# MCU_NAVSS0_RINGACC0_UDMASS_RINGACC0_CFG_MON register map
Vendor: Texas Instruments
Peripheral module from a debugger description file (folder J721S2).
Registers are 32-bit, read-write, reset 0x0 unless marked. A register's access mark holds for its fields unless they carry their own. Offsets are as the file gives them; lines under a group give offsets from that group; [hi:lo] are bit positions; {n}, {i} and the like mark numbered series; 'fields as' and 'values as' point back to an identical list; <NAME> marks a mode.

## MCU_NAVSS0_RINGACC0_UDMASS_RINGACC0_CFG_MON
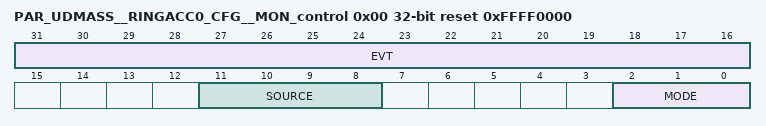
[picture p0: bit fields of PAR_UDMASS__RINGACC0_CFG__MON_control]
0x00 PAR_UDMASS__RINGACC0_CFG__MON_control reset 0xFFFF0000 — Monitor Control Register
  [31:16] EVT — Event to produce.
  [11:8] SOURCE — Monitor source selection. 0 = element count. 1 = reserved. 2 = reserved.
  [2:0] MODE — Monitor Mode. 0 = disabled. 1 = push/pop statistics capture. 2 = low/high threshold checks. 3 = low/high watermarking. 4 = starvation counting.
0x04 PAR_UDMASS__RINGACC0_CFG__MON_queue — Monitor Queue Register
  [15:0] QUEUE — Queue to monitor.
0x08 PAR_UDMASS__RINGACC0_CFG__MON_data0 — Monitor Data Register
  [31:0] DATA — Monitor Data. For mode 1 this is read-only and number of pushes. For mode 2 this is read-write and the low threshold value. For mode 3 this is read only and the low watermark. For mode 4 this is read only and the starvation count.
0x0C PAR_UDMASS__RINGACC0_CFG__MON_data1 — Monitor Data Register
  [31:0] DATA — Monitor Data. For mode 1 this is read-only and number of pops. For mode 2 this is read-write and the high threshold value. For mode 3 this is read only and the high watermark. For mode 4 this is not used.
